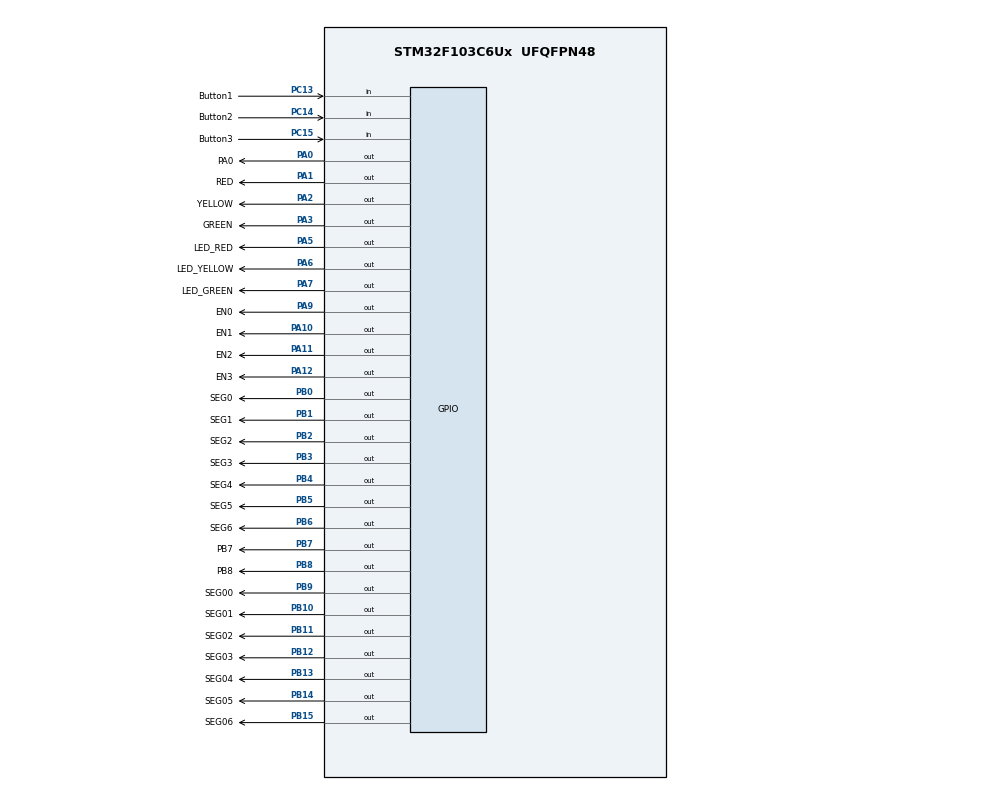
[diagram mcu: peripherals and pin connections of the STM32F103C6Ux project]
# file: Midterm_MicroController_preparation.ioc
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Mcu.Family=STM32F1
Mcu.Name=STM32F103C6Ux
Mcu.Package=UFQFPN48
NVIC.PriorityGroup=NVIC_PRIORITYGROUP_4
NVIC.TIM2_IRQn=true\:0\:0\:false\:false\:true\:true\:true
PA0-WKUP.GPIO_Label=PA0
PA0-WKUP.Signal=GPIO_Output
PA1.GPIO_Label=RED
PA1.Signal=GPIO_Output
PA10.GPIO_Label=EN1
PA10.Signal=GPIO_Output
PA11.GPIO_Label=EN2
PA11.Signal=GPIO_Output
PA12.GPIO_Label=EN3
PA12.Signal=GPIO_Output
PA13.Mode=Serial_Wire
PA13.Signal=SYS_JTMS-SWDIO
PA14.Mode=Serial_Wire
PA14.Signal=SYS_JTCK-SWCLK
PA2.GPIO_Label=YELLOW
PA2.Signal=GPIO_Output
PA3.GPIO_Label=GREEN
PA3.Signal=GPIO_Output
PA5.GPIO_Label=LED_RED
PA5.Signal=GPIO_Output
PA6.GPIO_Label=LED_YELLOW
PA6.Signal=GPIO_Output
PA7.GPIO_Label=LED_GREEN
PA7.Signal=GPIO_Output
PA9.GPIO_Label=EN0
PA9.Signal=GPIO_Output
PB0.GPIO_Label=SEG0
PB0.Signal=GPIO_Output
PB1.GPIO_Label=SEG1
PB1.Signal=GPIO_Output
PB10.GPIO_Label=SEG01
PB10.Signal=GPIO_Output
PB11.GPIO_Label=SEG02
PB11.Signal=GPIO_Output
PB12.GPIO_Label=SEG03
PB12.Signal=GPIO_Output
PB13.GPIO_Label=SEG04
PB13.Signal=GPIO_Output
PB14.GPIO_Label=SEG05
PB14.Signal=GPIO_Output
PB15.GPIO_Label=SEG06
PB15.Signal=GPIO_Output
PB2.GPIO_Label=SEG2
PB2.Signal=GPIO_Output
PB3.GPIO_Label=SEG3
PB3.Signal=GPIO_Output
PB4.GPIO_Label=SEG4
PB4.Signal=GPIO_Output
PB5.GPIO_Label=SEG5
PB5.Signal=GPIO_Output
PB6.GPIO_Label=SEG6
PB6.Signal=GPIO_Output
PB7.GPIO_Label=PB7
PB7.Signal=GPIO_Output
PB8.GPIO_Label=PB8
PB8.Signal=GPIO_Output
PB9.GPIO_Label=SEG00
PB9.Signal=GPIO_Output
PC13-TAMPER-RTC.GPIO_Label=Button1
PC13-TAMPER-RTC.GPIO_PuPd=GPIO_PULLUP
PC13-TAMPER-RTC.Signal=GPIO_Input
PC14-OSC32_IN.GPIO_Label=Button2
PC14-OSC32_IN.GPIO_PuPd=GPIO_PULLUP
PC14-OSC32_IN.Signal=GPIO_Input
PC15-OSC32_OUT.GPIO_Label=Button3
PC15-OSC32_OUT.GPIO_PuPd=GPIO_PULLUP
PC15-OSC32_OUT.Signal=GPIO_Input
ProjectManager.HeapSize=0x200
ProjectManager.StackSize=0x400
ProjectManager.TargetToolchain=STM32CubeIDE
RCC.APB1Freq_Value=8000000
RCC.APB2Freq_Value=8000000
TIM2.Period=9
TIM2.Prescaler=7999
VP_TIM2_VS_ClockSourceINT.Mode=Internal
board=custom

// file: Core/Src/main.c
/* USER CODE MIDTERM MICROCONTROLLER BEGIN Header */
/**
  ******************************************************************************
  * @file           : main.c
  * @brief          : Main program body
  ******************************************************************************
  * @attention
  *
  * <h2><center>&copy; Copyright (c) 2022 STMicroelectronics.
  * All rights reserved.</center></h2>
  *
  * This software component is licensed by ST under BSD 3-Clause license,
  * the "License"; You may not use this file except in compliance with the
  * License. You may obtain a copy of the License at:
  *                        opensource.org/licenses/BSD-3-Clause
  *
  ******************************************************************************
  */
/* USER CODE END Header */
#include "main.h"
#include "Button.h"
#include "Button2.h"
#include "Button3.h"
#include "software_timer.h"
#include "software_timer3.h"
#include "traffic_light.h"
#include "led7segment.h"
#include "fsm_mode0.h"

TIM_HandleTypeDef htim2;

void SystemClock_Config(void);
static void MX_GPIO_Init(void);
static void MX_TIM2_Init(void);

int main(void)
{

  /* MCU Configuration--------------------------------------------------------*/

  /* Reset of all peripherals, Initializes the Flash interface and the Systick. */
  HAL_Init();

  /* Configure the system clock */
  SystemClock_Config();

  /* Initialize all configured peripherals */
  MX_GPIO_Init();
  MX_TIM2_Init();
  /* USER CODE BEGIN 2 */

    /* USER CODE BEGIN 2 */

    /* USER CODE END 2 */

    HAL_GPIO_WritePin(LED_RED_GPIO_Port , LED_RED_Pin ,      SET)      ;
    HAL_GPIO_WritePin(LED_GREEN_GPIO_Port ,  LED_GREEN_Pin , RESET)      ;
    HAL_GPIO_WritePin(LED_YELLOW_GPIO_Port , LED_YELLOW_Pin, SET)      ;

    HAL_GPIO_WritePin(RED_GPIO_Port , RED_Pin ,        RESET)  ;
    HAL_GPIO_WritePin(GREEN_GPIO_Port ,  GREEN_Pin ,   RESET)  ;
    HAL_GPIO_WritePin(YELLOW_GPIO_Port , YELLOW_Pin,   RESET)  ;

      HAL_GPIO_WritePin(SEG00_GPIO_Port , SEG00_Pin , RESET )         ;
      HAL_GPIO_WritePin(SEG01_GPIO_Port , SEG01_Pin , RESET )         ;
      HAL_GPIO_WritePin(SEG02_GPIO_Port , SEG02_Pin , RESET )         ;
      HAL_GPIO_WritePin(SEG03_GPIO_Port , SEG03_Pin , RESET )         ;
      HAL_GPIO_WritePin(SEG04_GPIO_Port , SEG04_Pin , RESET )         ;
      HAL_GPIO_WritePin(SEG05_GPIO_Port , SEG05_Pin , RESET )         ;
      HAL_GPIO_WritePin(SEG06_GPIO_Port , SEG06_Pin , RESET )         ;

    HAL_GPIO_WritePin(SEG0_GPIO_Port , SEG0_Pin , RESET )         ;
    HAL_GPIO_WritePin(SEG1_GPIO_Port , SEG1_Pin , RESET )         ;
    HAL_GPIO_WritePin(SEG2_GPIO_Port , SEG2_Pin , RESET )         ;
    HAL_GPIO_WritePin(SEG3_GPIO_Port , SEG3_Pin , RESET )         ;
    HAL_GPIO_WritePin(SEG4_GPIO_Port , SEG4_Pin , RESET )         ;
    HAL_GPIO_WritePin(SEG5_GPIO_Port , SEG5_Pin , RESET )         ;
    HAL_GPIO_WritePin(SEG6_GPIO_Port , SEG6_Pin , RESET )         ;

    HAL_GPIO_WritePin(EN0_GPIO_Port , EN0_Pin , RESET )         ;
    HAL_GPIO_WritePin(EN1_GPIO_Port , EN1_Pin , RESET )         ;
    HAL_GPIO_WritePin(EN2_GPIO_Port , EN2_Pin , RESET )         ;
    HAL_GPIO_WritePin(EN3_GPIO_Port , EN3_Pin , RESET )         ;

    /* Infinite loop */
    HAL_TIM_Base_Start_IT(&htim2) ;
    void HAL_TIM_PeriodElapsedCallback(TIM_HandleTypeDef *htim);
    void display7SEG_internal(int count) ;
    void display7SEG(int count) ;
    COUNTER = 9 ; MODE = 0 ;   status2 = 0 ;

  /* USER CODE END 2 */

  /* Infinite loop */
      setTimer1(100) ;
      setTimer2(100) ;

  while (1)
  {

  }
}

void display7SEG_internal(int count){

 	switch(count){

 	    case 0:
 	 			HAL_GPIO_WritePin(SEG0_GPIO_Port , SEG0_Pin , RESET) ;
 	 	        HAL_GPIO_WritePin(SEG1_GPIO_Port , SEG1_Pin , RESET) ;
 	 			HAL_GPIO_WritePin(SEG2_GPIO_Port , SEG2_Pin , RESET) ;
 	 			HAL_GPIO_WritePin(SEG3_GPIO_Port , SEG3_Pin , RESET) ;
 	 		    HAL_GPIO_WritePin(SEG4_GPIO_Port , SEG4_Pin , RESET) ;
 	 	        HAL_GPIO_WritePin(SEG5_GPIO_Port , SEG5_Pin , RESET) ;
 	 		    HAL_GPIO_WritePin(SEG6_GPIO_Port , SEG6_Pin ,   SET) ;
 	 			break ;

 		case 1:

 			 HAL_GPIO_WritePin(SEG0_GPIO_Port , SEG0_Pin ,   SET) ;
 			 HAL_GPIO_WritePin(SEG1_GPIO_Port , SEG1_Pin , RESET) ;
 			 HAL_GPIO_WritePin(SEG2_GPIO_Port , SEG2_Pin , RESET) ;
 			 HAL_GPIO_WritePin(SEG3_GPIO_Port , SEG3_Pin ,   SET) ;
 			 HAL_GPIO_WritePin(SEG4_GPIO_Port , SEG4_Pin ,   SET) ;
 			 HAL_GPIO_WritePin(SEG5_GPIO_Port , SEG5_Pin ,   SET) ;
 			 HAL_GPIO_WritePin(SEG6_GPIO_Port , SEG6_Pin ,   SET) ;
 			 break ;

 		case 2:

 			HAL_GPIO_WritePin(SEG0_GPIO_Port , SEG0_Pin , RESET) ;
 	        HAL_GPIO_WritePin(SEG1_GPIO_Port , SEG1_Pin , RESET) ;
 			HAL_GPIO_WritePin(SEG2_GPIO_Port , SEG2_Pin , SET) ;
 			HAL_GPIO_WritePin(SEG3_GPIO_Port , SEG3_Pin , RESET) ;
 		    HAL_GPIO_WritePin(SEG4_GPIO_Port , SEG4_Pin , RESET) ;
 	        HAL_GPIO_WritePin(SEG5_GPIO_Port , SEG5_Pin , SET) ;
 		    HAL_GPIO_WritePin(SEG6_GPIO_Port , SEG6_Pin , RESET) ;
 			break ;

 		case 3:

 			HAL_GPIO_WritePin(SEG0_GPIO_Port , SEG0_Pin , RESET) ;
 	        HAL_GPIO_WritePin(SEG1_GPIO_Port , SEG1_Pin , RESET) ;
 			HAL_GPIO_WritePin(SEG2_GPIO_Port , SEG2_Pin , RESET) ;
     		HAL_GPIO_WritePin(SEG3_GPIO_Port , SEG3_Pin , RESET) ;
 		    HAL_GPIO_WritePin(SEG4_GPIO_Port , SEG4_Pin ,   SET) ;
 	        HAL_GPIO_WritePin(SEG5_GPIO_Port , SEG5_Pin ,   SET) ;
 	        HAL_GPIO_WritePin(SEG6_GPIO_Port , SEG6_Pin , RESET) ;
 			break ;

 		case 4:
 		 	HAL_GPIO_WritePin(SEG0_GPIO_Port , SEG0_Pin ,   SET) ;
 		 	HAL_GPIO_WritePin(SEG1_GPIO_Port , SEG1_Pin , RESET) ;
 		 	HAL_GPIO_WritePin(SEG2_GPIO_Port , SEG2_Pin , RESET) ;
 		 	HAL_GPIO_WritePin(SEG3_GPIO_Port , SEG3_Pin ,   SET) ;
 		    HAL_GPIO_WritePin(SEG4_GPIO_Port , SEG4_Pin ,   SET) ;
 		    HAL_GPIO_WritePin(SEG5_GPIO_Port , SEG5_Pin , RESET) ;
 		 	HAL_GPIO_WritePin(SEG6_GPIO_Port , SEG6_Pin , RESET) ;
 		    break ;

 		case 5:
 			HAL_GPIO_WritePin(SEG0_GPIO_Port , SEG0_Pin , RESET) ;
 			HAL_GPIO_WritePin(SEG1_GPIO_Port , SEG1_Pin ,   SET) ;
 			HAL_GPIO_WritePin(SEG2_GPIO_Port , SEG2_Pin , RESET) ;
 			HAL_GPIO_WritePin(SEG3_GPIO_Port , SEG3_Pin , RESET) ;
 		    HAL_GPIO_WritePin(SEG4_GPIO_Port , SEG4_Pin ,   SET) ;
 		    HAL_GPIO_WritePin(SEG5_GPIO_Port , SEG5_Pin , RESET) ;
 		    HAL_GPIO_WritePin(SEG6_GPIO_Port , SEG6_Pin , RESET) ;
 			break ;

 		case 6:
 			HAL_GPIO_WritePin(SEG0_GPIO_Port , SEG0_Pin , RESET) ;
 		    HAL_GPIO_WritePin(SEG1_GPIO_Port , SEG1_Pin ,   SET) ;
 		 	HAL_GPIO_WritePin(SEG2_GPIO_Port , SEG2_Pin , RESET) ;
 		 	HAL_GPIO_WritePin(SEG3_GPIO_Port , SEG3_Pin , RESET) ;
 		    HAL_GPIO_WritePin(SEG4_GPIO_Port , SEG4_Pin , RESET) ;
 		 	HAL_GPIO_WritePin(SEG5_GPIO_Port , SEG5_Pin , RESET) ;
 		 	HAL_GPIO_WritePin(SEG6_GPIO_Port , SEG6_Pin , RESET) ;
 			break;

 		case 7:
 			HAL_GPIO_WritePin(SEG0_GPIO_Port , SEG0_Pin , RESET) ;
 			HAL_GPIO_WritePin(SEG1_GPIO_Port , SEG1_Pin , RESET) ;
 			HAL_GPIO_WritePin(SEG2_GPIO_Port , SEG2_Pin , RESET) ;
 			HAL_GPIO_WritePin(SEG3_GPIO_Port , SEG3_Pin ,   SET) ;
 			HAL_GPIO_WritePin(SEG4_GPIO_Port , SEG4_Pin ,   SET) ;
 			HAL_GPIO_WritePin(SEG5_GPIO_Port , SEG5_Pin ,   SET) ;
 			HAL_GPIO_WritePin(SEG6_GPIO_Port , SEG6_Pin ,   SET) ;
 			break ;

 		case 8:
 			HAL_GPIO_WritePin(SEG0_GPIO_Port , SEG0_Pin , RESET) ;
 		 	HAL_GPIO_WritePin(SEG1_GPIO_Port , SEG1_Pin , RESET) ;
 		 	HAL_GPIO_WritePin(SEG2_GPIO_Port , SEG2_Pin , RESET) ;
 		 	HAL_GPIO_WritePin(SEG3_GPIO_Port , SEG3_Pin , RESET) ;
 		    HAL_GPIO_WritePin(SEG4_GPIO_Port , SEG4_Pin , RESET) ;
 	        HAL_GPIO_WritePin(SEG5_GPIO_Port , SEG5_Pin , RESET) ;
 		    HAL_GPIO_WritePin(SEG6_GPIO_Port , SEG6_Pin , RESET) ;
 			break ;

 		case 9:
 			HAL_GPIO_WritePin(SEG0_GPIO_Port , SEG0_Pin , RESET) ;
 			HAL_GPIO_WritePin(SEG1_GPIO_Port , SEG1_Pin , RESET) ;
 			HAL_GPIO_WritePin(SEG2_GPIO_Port , SEG2_Pin , RESET) ;
 			HAL_GPIO_WritePin(SEG3_GPIO_Port , SEG3_Pin , RESET) ;
 		    HAL_GPIO_WritePin(SEG4_GPIO_Port , SEG4_Pin ,   SET) ;
 		    HAL_GPIO_WritePin(SEG5_GPIO_Port , SEG5_Pin , RESET) ;
 	        HAL_GPIO_WritePin(SEG6_GPIO_Port , SEG6_Pin , RESET) ;
 			break ;

 	}

 } ;

int count_long_pressed = 300 ;
void HAL_TIM_PeriodElapsedCallback(TIM_HandleTypeDef *htim){

	              display7SEG(COUNTER) ;

	          timerRun1();
	          timerRun2();
	          timerRun3();
	          timerRun4();
	          getKeyInput1()      ;
	          getKeyInput2()      ;
	          getKeyInput3()      ;
	          fsm_Mode0_run()     ;
	          if(timer2_flag == 1){HAL_GPIO_TogglePin(LED_RED_GPIO_Port , LED_RED_Pin) ;
	                               setTimer2(100) ; }

	          //fsm_automatic_run() ;
};
void SystemClock_Config(void)
{
  RCC_OscInitTypeDef RCC_OscInitStruct = {0};
  RCC_ClkInitTypeDef RCC_ClkInitStruct = {0};

  /** Initializes the RCC Oscillators according to the specified parameters
  * in the RCC_OscInitTypeDef structure.
  */
  RCC_OscInitStruct.OscillatorType = RCC_OSCILLATORTYPE_HSI;
  RCC_OscInitStruct.HSIState = RCC_HSI_ON;
  RCC_OscInitStruct.HSICalibrationValue = RCC_HSICALIBRATION_DEFAULT;
  RCC_OscInitStruct.PLL.PLLState = RCC_PLL_NONE;
  if (HAL_RCC_OscConfig(&RCC_OscInitStruct) != HAL_OK)
  {
    Error_Handler();
  }
  /** Initializes the CPU, AHB and APB buses clocks
  */
  RCC_ClkInitStruct.ClockType = RCC_CLOCKTYPE_HCLK|RCC_CLOCKTYPE_SYSCLK
                              |RCC_CLOCKTYPE_PCLK1|RCC_CLOCKTYPE_PCLK2;
  RCC_ClkInitStruct.SYSCLKSource = RCC_SYSCLKSOURCE_HSI;
  RCC_ClkInitStruct.AHBCLKDivider = RCC_SYSCLK_DIV1;
  RCC_ClkInitStruct.APB1CLKDivider = RCC_HCLK_DIV1;
  RCC_ClkInitStruct.APB2CLKDivider = RCC_HCLK_DIV1;

  if (HAL_RCC_ClockConfig(&RCC_ClkInitStruct, FLASH_LATENCY_0) != HAL_OK)
  {
    Error_Handler();
  }
}

static void MX_TIM2_Init(void)
{

  TIM_ClockConfigTypeDef sClockSourceConfig = {0};
  TIM_MasterConfigTypeDef sMasterConfig = {0};

  htim2.Instance = TIM2;
  htim2.Init.Prescaler = 7999;
  htim2.Init.CounterMode = TIM_COUNTERMODE_UP;
  htim2.Init.Period = 9;
  htim2.Init.ClockDivision = TIM_CLOCKDIVISION_DIV1;
  htim2.Init.AutoReloadPreload = TIM_AUTORELOAD_PRELOAD_DISABLE;
  if (HAL_TIM_Base_Init(&htim2) != HAL_OK)
  {
    Error_Handler();
  }
  sClockSourceConfig.ClockSource = TIM_CLOCKSOURCE_INTERNAL;
  if (HAL_TIM_ConfigClockSource(&htim2, &sClockSourceConfig) != HAL_OK)
  {
    Error_Handler();
  }
  sMasterConfig.MasterOutputTrigger = TIM_TRGO_RESET;
  sMasterConfig.MasterSlaveMode = TIM_MASTERSLAVEMODE_DISABLE;
  if (HAL_TIMEx_MasterConfigSynchronization(&htim2, &sMasterConfig) != HAL_OK)
  {
    Error_Handler();
  }

}

static void MX_GPIO_Init(void)
{
  GPIO_InitTypeDef GPIO_InitStruct = {0};

  /* GPIO Ports Clock Enable */
  __HAL_RCC_GPIOC_CLK_ENABLE();
  __HAL_RCC_GPIOA_CLK_ENABLE();
  __HAL_RCC_GPIOB_CLK_ENABLE();

  /*Configure GPIO pin Output Level */
  HAL_GPIO_WritePin(GPIOA, PA0_Pin|RED_Pin|YELLOW_Pin|GREEN_Pin
                          |LED_RED_Pin|LED_YELLOW_Pin|LED_GREEN_Pin|EN0_Pin
                          |EN1_Pin|EN2_Pin|EN3_Pin, GPIO_PIN_RESET);

  /*Configure GPIO pin Output Level */
  HAL_GPIO_WritePin(GPIOB, SEG0_Pin|SEG1_Pin|SEG2_Pin|SEG01_Pin
                          |SEG02_Pin|SEG03_Pin|SEG04_Pin|SEG05_Pin
                          |SEG06_Pin|SEG3_Pin|SEG4_Pin|SEG5_Pin
                          |SEG6_Pin|PB7_Pin|PB8_Pin|SEG00_Pin, GPIO_PIN_RESET);

  /*Configure GPIO pins : Button1_Pin Button2_Pin Button3_Pin */
  GPIO_InitStruct.Pin = Button1_Pin|Button2_Pin|Button3_Pin;
  GPIO_InitStruct.Mode = GPIO_MODE_INPUT;
  GPIO_InitStruct.Pull = GPIO_PULLUP;
  HAL_GPIO_Init(GPIOC, &GPIO_InitStruct);

  /*Configure GPIO pins : PA0_Pin RED_Pin YELLOW_Pin GREEN_Pin
                           LED_RED_Pin LED_YELLOW_Pin LED_GREEN_Pin EN0_Pin
                           EN1_Pin EN2_Pin EN3_Pin */
  GPIO_InitStruct.Pin = PA0_Pin|RED_Pin|YELLOW_Pin|GREEN_Pin
                          |LED_RED_Pin|LED_YELLOW_Pin|LED_GREEN_Pin|EN0_Pin
                          |EN1_Pin|EN2_Pin|EN3_Pin;
  GPIO_InitStruct.Mode = GPIO_MODE_OUTPUT_PP;
  GPIO_InitStruct.Pull = GPIO_NOPULL;
  GPIO_InitStruct.Speed = GPIO_SPEED_FREQ_LOW;
  HAL_GPIO_Init(GPIOA, &GPIO_InitStruct);

  /*Configure GPIO pins : SEG0_Pin SEG1_Pin SEG2_Pin SEG01_Pin
                           SEG02_Pin SEG03_Pin SEG04_Pin SEG05_Pin
                           SEG06_Pin SEG3_Pin SEG4_Pin SEG5_Pin
                           SEG6_Pin PB7_Pin PB8_Pin SEG00_Pin */
  GPIO_InitStruct.Pin = SEG0_Pin|SEG1_Pin|SEG2_Pin|SEG01_Pin
                          |SEG02_Pin|SEG03_Pin|SEG04_Pin|SEG05_Pin
                          |SEG06_Pin|SEG3_Pin|SEG4_Pin|SEG5_Pin
                          |SEG6_Pin|PB7_Pin|PB8_Pin|SEG00_Pin;
  GPIO_InitStruct.Mode = GPIO_MODE_OUTPUT_PP;
  GPIO_InitStruct.Pull = GPIO_NOPULL;
  GPIO_InitStruct.Speed = GPIO_SPEED_FREQ_LOW;
  HAL_GPIO_Init(GPIOB, &GPIO_InitStruct);

}

void Error_Handler(void)
{
  __disable_irq();
  while (1)
  {
  }
}

/************************ (C) COPYRIGHT STMicroelectronics *****END OF FILE****/
